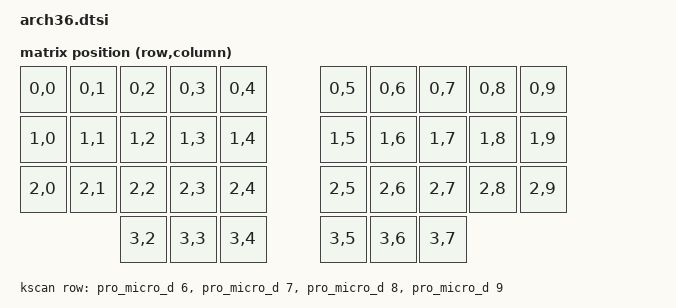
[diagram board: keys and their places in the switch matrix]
// This file was generated from a template. Edit it to match your keyboard.
// See https://zmk.dev/docs/development/hardware-integration/new-shield for more
// instructions.

#include <dt-bindings/zmk/matrix_transform.h>

#include "arch36-layouts.dtsi"

/ {
    chosen {
        zmk,physical-layout = &default_layout;
    };

    kscan: kscan {
        // If the hardware does not use a switch matrix, change this to the
        // appropriate driver and update the properties below to match.
        // See https://zmk.dev/docs/config/kscan for supported key scan drivers.
        compatible = "zmk,kscan-gpio-matrix";
        // Set this to "col2row" or "row2col" to match the hardware. If using
        // "row2col", change the col-gpios in the _left.overlay and _right.overlay
        // files to (GPIO_ACTIVE_HIGH | GPIO_PULL_DOWN) and the row-gpios here to
        // GPIO_ACTIVE_HIGH.
        diode-direction = "col2row";
        wakeup-source;

        // Replace these comments with the GPIO pins in the matrix.
        // See https://zmk.dev/docs/development/hardware-integration/new-shield#shield-overlays
        row-gpios
            = <&pro_micro_d 6 (GPIO_ACTIVE_HIGH | GPIO_PULL_DOWN)>
            , <&pro_micro_d 7 (GPIO_ACTIVE_HIGH | GPIO_PULL_DOWN)>
            , <&pro_micro_d 8 (GPIO_ACTIVE_HIGH | GPIO_PULL_DOWN)>
            , <&pro_micro_d 9 (GPIO_ACTIVE_HIGH | GPIO_PULL_DOWN)>
            ;
    };

    default_transform: default_transform {
        // See https://zmk.dev/docs/development/hardware-integration/new-shield#matrix-transform
        // for how to configure this
        compatible = "zmk,matrix-transform";
        columns = <10>;
        rows = <4>;
// | SW2  | SW3  | SW4  | SW5  | SW6  |   | SW6  | SW5  | SW4  | SW3  | SW2  |
// | SW8  | SW9  | SW10 | SW11 | SW12 |   | SW12 | SW11 | SW10 | SW9  | SW8  |
// | SW14 | SW15 | SW16 | SW17 | SW18 |   | SW18 | SW17 | SW16 | SW15 | SW14 |
//               | SW19 | SW20 | SW21 |   | SW21 | SW20 | SW19 |
        map = <
RC(0,0) RC(0,1) RC(0,2) RC(0,3) RC(0,4) RC(0,5) RC(0,6) RC(0,7) RC(0,8) RC(0,9)
RC(1,0) RC(1,1) RC(1,2) RC(1,3) RC(1,4) RC(1,5) RC(1,6) RC(1,7) RC(1,8) RC(1,9)
RC(2,0) RC(2,1) RC(2,2) RC(2,3) RC(2,4) RC(2,5) RC(2,6) RC(2,7) RC(2,8) RC(2,9)
                RC(3,2) RC(3,3) RC(3,4) RC(3,5) RC(3,6) RC(3,7)
        >;
    };
};
